# CY8C5888LTI_LP097 register map
File version: 0.1
CY8C58LP
Registers are 8-bit, read-write, no defined reset value unless marked. A register's access mark holds for its fields unless they carry their own. Offsets are from the block's base; lines under a group give offsets from that group; [hi:lo] are bit positions; {n}, {i} and the like mark numbered series; 'fields as' and 'values as' point back to an identical list; <NAME> marks a mode.

## Memory map
0x00000000 MIDI2_UART — UART
0x00000000 MIDI1_UART — UART
0x00000000 USB — USBFS
0x00000000 SleepTimer
0x40006472 Control_Reg_11
0x40006474 Control_Reg_10
0x40006475 Tabs_2
0x40006476 Tabs_4
0x40006478 Keys_Notes_1
0x40006479 Keys_Notes_5
0x4000647A Keys_Notes_4
0x4000647B Keys_Notes_2
0x4000647D Keys_Notes_3
0x40006574 Bass_Notes
0x40006575 Chorus_Speed
0x40006577 Tabs_1
0x40006578 Tabs_3
0x40006579 Keys_Notes_6
0x4000657A Chords_Bass_Notes
0x4000657B Chords_Notes

## Keys_Notes_1
Base 0x40006478
0x00 Keys_Notes_1_CONTROL_REG

## Keys_Notes_3
Base 0x4000647D
Registers as Keys_Notes_1 (with Keys_Notes_1 read as Keys_Notes_3).

## Keys_Notes_4
Base 0x4000647A
Registers as Keys_Notes_1 (with Keys_Notes_1 read as Keys_Notes_4).

## Keys_Notes_2
Base 0x4000647B
Registers as Keys_Notes_1 (with Keys_Notes_1 read as Keys_Notes_2).

## Tabs_2
Base 0x40006475
Registers as Keys_Notes_1 (with Keys_Notes_1 read as Tabs_2).

## Tabs_3
Base 0x40006578
Registers as Keys_Notes_1 (with Keys_Notes_1 read as Tabs_3).

## Tabs_1
Base 0x40006577
Registers as Keys_Notes_1 (with Keys_Notes_1 read as Tabs_1).

## Control_Reg_11
Base 0x40006472
Registers as Keys_Notes_1 (with Keys_Notes_1 read as Control_Reg_11).

## Chorus_Speed
Base 0x40006575
Registers as Keys_Notes_1 (with Keys_Notes_1 read as Chorus_Speed).

## Tabs_4
Base 0x40006476
Registers as Keys_Notes_1 (with Keys_Notes_1 read as Tabs_4).

## Keys_Notes_5
Base 0x40006479
Registers as Keys_Notes_1 (with Keys_Notes_1 read as Keys_Notes_5).

## Bass_Notes
Base 0x40006574
Registers as Keys_Notes_1 (with Keys_Notes_1 read as Bass_Notes).

## Control_Reg_10
Base 0x40006474
Registers as Keys_Notes_1 (with Keys_Notes_1 read as Control_Reg_10).

## Chords_Bass_Notes
Base 0x4000657A
Registers as Keys_Notes_1 (with Keys_Notes_1 read as Chords_Bass_Notes).

## Keys_Notes_6
Base 0x40006579
Registers as Keys_Notes_1 (with Keys_Notes_1 read as Keys_Notes_6).

## Chords_Notes
Base 0x4000657B
Registers as Keys_Notes_1 (with Keys_Notes_1 read as Chords_Notes).

## MIDI2_UART — UART
Base 0x00000000
0x4000642C RX_MIDI2_UART_RX_ADDRESS1 — RX Address1 Register
0x4000643C RX_MIDI2_UART_RX_ADDRESS2 — RX Address2 Register
0x40006443 TX_MIDI2_UART_TX_DATA — TX Data Register
0x4000644C RX_MIDI2_UART_RX_DATA — RX Data Register
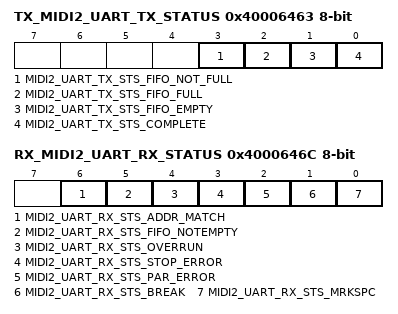
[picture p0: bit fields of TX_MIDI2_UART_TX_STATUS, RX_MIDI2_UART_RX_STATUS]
0x40006463 TX_MIDI2_UART_TX_STATUS — TX status register
  [3] MIDI2_UART_TX_STS_FIFO_NOT_FULL ro, [2] MIDI2_UART_TX_STS_FIFO_FULL ro, [1] MIDI2_UART_TX_STS_FIFO_EMPTY ro, [0] MIDI2_UART_TX_STS_COMPLETE ro
0x4000646C RX_MIDI2_UART_RX_STATUS — RX status register
  [6] MIDI2_UART_RX_STS_ADDR_MATCH ro, [5] MIDI2_UART_RX_STS_FIFO_NOTEMPTY ro, [4] MIDI2_UART_RX_STS_OVERRUN ro, [3] MIDI2_UART_RX_STS_STOP_ERROR ro, [2] MIDI2_UART_RX_STS_PAR_ERROR ro, [1] MIDI2_UART_RX_STS_BREAK ro, [0] MIDI2_UART_RX_STS_MRKSPC ro

## MIDI1_UART — UART
Base 0x00000000
0x40006429 RX_MIDI1_UART_RX_ADDRESS1 — RX Address1 Register
0x40006439 RX_MIDI1_UART_RX_ADDRESS2 — RX Address2 Register
0x40006447 TX_MIDI1_UART_TX_DATA — TX Data Register
0x40006449 RX_MIDI1_UART_RX_DATA — RX Data Register
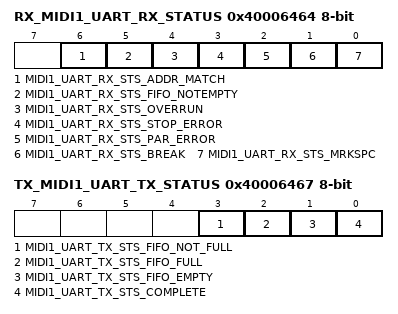
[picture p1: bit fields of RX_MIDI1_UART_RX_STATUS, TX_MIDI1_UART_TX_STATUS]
0x40006464 RX_MIDI1_UART_RX_STATUS — RX status register
  [6] MIDI1_UART_RX_STS_ADDR_MATCH ro, [5] MIDI1_UART_RX_STS_FIFO_NOTEMPTY ro, [4] MIDI1_UART_RX_STS_OVERRUN ro, [3] MIDI1_UART_RX_STS_STOP_ERROR ro, [2] MIDI1_UART_RX_STS_PAR_ERROR ro, [1] MIDI1_UART_RX_STS_BREAK ro, [0] MIDI1_UART_RX_STS_MRKSPC ro
0x40006467 TX_MIDI1_UART_TX_STATUS — TX status register
  [3] MIDI1_UART_TX_STS_FIFO_NOT_FULL ro, [2] MIDI1_UART_TX_STS_FIFO_FULL ro, [1] MIDI1_UART_TX_STS_FIFO_EMPTY ro, [0] MIDI1_UART_TX_STS_COMPLETE ro
